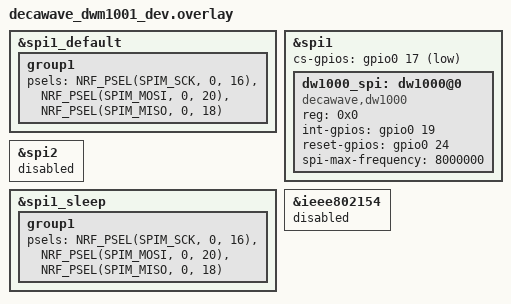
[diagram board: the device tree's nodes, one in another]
&spi1_default {
	group1 {
		psels = <NRF_PSEL(SPIM_SCK, 0, 16)>,
				<NRF_PSEL(SPIM_MOSI, 0, 20)>,
				<NRF_PSEL(SPIM_MISO, 0, 18)>;
	};
};

&spi1 {
	cs-gpios = <&gpio0 17 (GPIO_PULL_UP | GPIO_ACTIVE_LOW)>;
	dw1000_spi: dw1000@0 {
		compatible = "decawave,dw1000";
		reg = <0x0>;
		int-gpios = <&gpio0 19 0>;
		reset-gpios = <&gpio0 24 0>;
		spi-max-frequency = <8000000>;
	};
};

&spi2 {
	status = "disabled";
};

&spi1_sleep {
	group1 {
		psels = <NRF_PSEL(SPIM_SCK, 0, 16)>,
				<NRF_PSEL(SPIM_MOSI, 0, 20)>,
				<NRF_PSEL(SPIM_MISO, 0, 18)>;
	};
};

&ieee802154 {
	status = "disabled";
};
